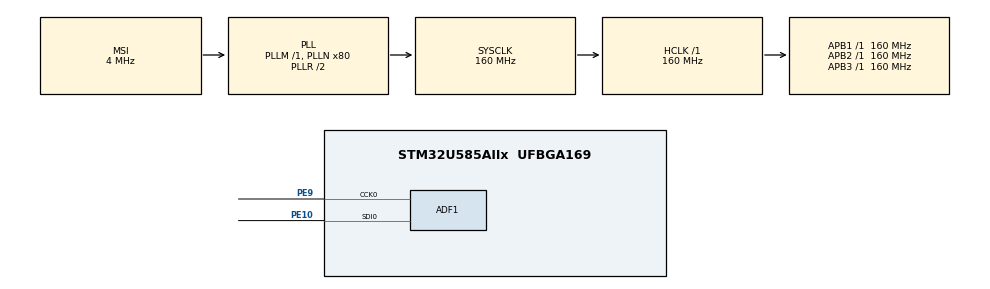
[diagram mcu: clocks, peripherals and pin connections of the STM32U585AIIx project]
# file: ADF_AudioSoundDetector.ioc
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ADF1.MDF_COMPARAM_ActivationOutputClock=ENABLE
ADF1.MDF_COMPARAM_Divider=4
ADF1.MDF_DFLT0_Decimation=64
ADF1.MDF_DFLT0_SADActivation=ENABLE
ADF1.MDF_DFLT0_SADDataMemoryTransfer=MDF_SAD_MEMORY_TRANSFER_ALWAYS
ADF1.MDF_DFLT0_SADMinNoiseLevel=200
ADF1.MDF_DFLT0_SADSignalNoiseThreshold=MDF_SAD_SIGNAL_NOISE_18DB
ADF1.MDF_SITF0_Mode_Display=MDF_SITF_NORMAL_SPI_MODE
ADF1.MDF_SITF0_Threshold=31
CORTEX_M33_NS.userName=CORTEX_M33
LPDMA1.LINKALLOCATEDPORT_LPDMACH0=DMA_LINK_ALLOCATED_PORT1
LPDMA1.LINKEDLISTMODE_LPDMACH0=DMA_LINKEDLIST_CIRCULAR
LPDMA1.PRIORITY_LL_LPDMACH0=DMA_LOW_PRIORITY_HIGH_WEIGHT
Linkedlist.MDMA_Channel0.GP_SW.0.BlkHWRequest=DMA_BREQ_SINGLE_BURST
Linkedlist.MDMA_Channel0.GP_SW.0.DataHandling=NONE
Linkedlist.MDMA_Channel0.GP_SW.0.DataSize=0
Linkedlist.MDMA_Channel0.GP_SW.0.DestDataWidth=DMA_DEST_DATAWIDTH_WORD
Linkedlist.MDMA_Channel0.GP_SW.0.DestInc=DMA_DINC_INCREMENTED
Linkedlist.MDMA_Channel0.GP_SW.0.Direction=DMA_PERIPH_TO_MEMORY
Linkedlist.MDMA_Channel0.GP_SW.0.DstAddress=0
Linkedlist.MDMA_Channel0.GP_SW.0.Instance=MDMA_Channel0
Linkedlist.MDMA_Channel0.GP_SW.0.LL_MASTERDMA=LPDMA
Linkedlist.MDMA_Channel0.GP_SW.0.LL_NAME=MDFQueue
Linkedlist.MDMA_Channel0.GP_SW.0.LL_TYPE=LINEAR
Linkedlist.MDMA_Channel0.GP_SW.0.NODE_NAME=MDFNode
Linkedlist.MDMA_Channel0.GP_SW.0.Requestforcodegen=LPDMA1_REQUEST_ADF1_FLT0
Linkedlist.MDMA_Channel0.GP_SW.0.SrcAddress=0
Linkedlist.MDMA_Channel0.GP_SW.0.SrcDataWidth=DMA_SRC_DATAWIDTH_WORD
Linkedlist.MDMA_Channel0.GP_SW.0.SrcInc=DMA_SINC_FIXED
Linkedlist.MDMA_Channel0.GP_SW.0.TransferEventMode=DMA_TCEM_BLOCK_TRANSFER
Linkedlist.MDMA_Channel0.GP_SW.0.TriggerPolarity=DMA_TRIG_POLARITY_MASKED
Linkedlist.MDMA_Channel0.Request0=GP_SW
Linkedlist.MDMA_Channel0.RequestsNb=1
Linkedlist.RequestSet0=MDMA_Channel0
Linkedlist.RequestSetsNb=1
Mcu.Family=STM32U5
Mcu.Name=STM32U585AIIx
Mcu.Package=UFBGA169
NVIC.ADF1_IRQn=true\:0\:0\:false\:false\:true\:true\:true\:true
NVIC.LPDMA1_Channel0_IRQn=true\:0\:0\:false\:false\:true\:true\:true\:true
NVIC.PriorityGroup=NVIC_PRIORITYGROUP_4
PE10.Mode=MOD_ADF_CCK
PE10.Signal=ADF1_SDI0
PE9.Mode=MOD_MDF_CCK0
PE9.Signal=ADF1_CCK0
PWR.PowerMode=PWR_SMPS_SUPPLY
ProjectManager.HeapSize=0x200
ProjectManager.StackSize=0x400
ProjectManager.TargetToolchain=EWARM V8.50
RCC.ADCFreq_Value=16000000
RCC.AHBFreq_Value=160000000
RCC.APB1Freq_Value=160000000
RCC.APB1TimFreq_Value=160000000
RCC.APB2Freq_Value=160000000
RCC.APB2TimFreq_Value=160000000
RCC.APB3Freq_Value=160000000
RCC.AdfClockSelection=RCC_ADF1CLKSOURCE_MSIK
RCC.CortexFreq_Value=160000000
RCC.DACCLockSelectionVirtual=RCC_DAC1CLKSOURCE_LSI
RCC.DACCLockSelectionVirtualString=RCC_DAC1CLKSOURCE_LSI
RCC.EPOD_VALUE=4000000
RCC.HCLKFreq_Value=160000000
RCC.HSE_VALUE=16000000
RCC.HSI48_VALUE=48000000
RCC.HSI_VALUE=16000000
RCC.LSE_VALUE=32768
RCC.LSIDIV_VALUE=32000
RCC.MSIKClockRange=RCC_MSIKRANGE_3
RCC.MSI_VALUE=4000000
RCC.PLLN=80
RCC.SYSCLKFreq_VALUE=160000000
RCC.SYSCLKSource=RCC_SYSCLKSOURCE_PLLCLK
RCC.USBFreq_Value=48000000
RCC.VCOOutputFreq_Value=320000000
VP_ICACHE_VS_ICACHE.Mode=DirectMappedCache
VP_LPBAMQUEUE_VS_QUEUE.Mode=QUEUEMODE
VP_LPBAM_VS_SIG1.Mode=SmartRun
VP_LPBAM_VS_SIG4.Mode=LPDMA1
VP_LPDMA1_VS_LPDMACH0.Mode=LINKEDLIST_LPDMACH0
VP_PWR_VS_DBSignals.Mode=DisableDeadBatterySignals
VP_PWR_VS_LPOM.Mode=PowerOptimisation
VP_PWR_VS_SECSignals.Mode=Security/Privilege
board=B-U585I-IOT02A

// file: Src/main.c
/* USER CODE BEGIN Header */
/**
  ******************************************************************************
  * @file           : main.c
  * @brief          : Main program body
  ******************************************************************************
  * @attention
  *
  * Copyright (c) 2021 STMicroelectronics.
  * All rights reserved.
  *
  * This software is licensed under terms that can be found in the LICENSE file
  * in the root directory of this software component.
  * If no LICENSE file comes with this software, it is provided AS-IS.
  *
  ******************************************************************************
  */
/* USER CODE END Header */
#include "main.h"

/* USER CODE BEGIN Includes */
#include "linked_list.h"
/* USER CODE END Includes */

MDF_HandleTypeDef AdfHandle0;
MDF_FilterConfigTypeDef AdfFilterConfig0;

DMA_HandleTypeDef handle_LPDMA1_Channel0;

/* USER CODE BEGIN PV */
MDF_DmaConfigTypeDef    DMAConfig;

/*Buffer location and size should aligned to cache line size (32 bytes) */
int16_t RecBuff[REC_BUFF_SIZE * 2U];
/* USER CODE END PV */

void SystemClock_Config(void);
static void SystemPower_Config(void);
static void MX_ICACHE_Init(void);
static void MX_GPIO_Init(void);
static void MX_ADF1_Init(void);
static void MX_LPDMA1_Init(void);
/* USER CODE BEGIN PFP */
static void MDF_DMAConfig(void);
static void EnterLowPowerMode(void);
/* USER CODE END PFP */

/* USER CODE BEGIN 0 */
extern DMA_QListTypeDef MDFQueue;
/* USER CODE END 0 */

int main(void)
{
  /* USER CODE BEGIN 1 */
  /* STM32U5xx HAL library initialization:
       - Configure the Flash prefetch
       - Configure the Systick to generate an interrupt each 1 msec
       - Set NVIC Group Priority to 3
       - Low Level Initialization
     */
  /* USER CODE END 1 */

  /* MCU Configuration--------------------------------------------------------*/

  /* Reset of all peripherals, Initializes the Flash interface and the Systick. */
  HAL_Init();

  /* Configure the system clock */
  SystemClock_Config();

  /* Configure the System Power */
  SystemPower_Config();

  /* Initialize all configured peripherals */
  MX_ICACHE_Init();
  MX_GPIO_Init();
  MX_ADF1_Init();
  MX_LPDMA1_Init();
  /* USER CODE BEGIN 2 */
  BSP_LED_Init(LED_GREEN);
  BSP_LED_Init(LED_RED);
  MX_MDFQueue_Config();

  /* Set queue circular mode for sai queue */
  HAL_DMAEx_List_SetCircularMode(&MDFQueue);

    /* Link SAI queue to DMA channel */
  HAL_DMAEx_List_LinkQ(&handle_LPDMA1_Channel0, &MDFQueue);

  /* Associate the DMA handle */
  __HAL_LINKDMA(&AdfHandle0, hdma, handle_LPDMA1_Channel0);

  /* Configure MDF DMA */
  MDF_DMAConfig();

  /* Start MDF Acquisition */
  if (HAL_MDF_AcqStart_DMA(&AdfHandle0, &AdfFilterConfig0, &DMAConfig) != HAL_OK)
  {
    Error_Handler();
  }
  /* USER CODE END 2 */

  /* Infinite loop */
  /* USER CODE BEGIN WHILE */
  while (1)
  {
    /* Enter the system to Stop 2 mode */
    EnterLowPowerMode();
    /* USER CODE END WHILE */

  }
}

void SystemClock_Config(void)
{
  RCC_OscInitTypeDef RCC_OscInitStruct = {0};
  RCC_ClkInitTypeDef RCC_ClkInitStruct = {0};

  /** Configure the main internal regulator output voltage
  */
  if (HAL_PWREx_ControlVoltageScaling(PWR_REGULATOR_VOLTAGE_SCALE1) != HAL_OK)
  {
    Error_Handler();
  }

  /** Initializes the CPU, AHB and APB busses clocks
  */
  RCC_OscInitStruct.OscillatorType = RCC_OSCILLATORTYPE_MSI|RCC_OSCILLATORTYPE_MSIK;
  RCC_OscInitStruct.MSIState = RCC_MSI_ON;
  RCC_OscInitStruct.MSICalibrationValue = RCC_MSICALIBRATION_DEFAULT;
  RCC_OscInitStruct.MSIClockRange = RCC_MSIRANGE_4;
  RCC_OscInitStruct.MSIKClockRange = RCC_MSIKRANGE_3;
  RCC_OscInitStruct.MSIKState = RCC_MSIK_ON;
  RCC_OscInitStruct.PLL.PLLState = RCC_PLL_ON;
  RCC_OscInitStruct.PLL.PLLSource = RCC_PLLSOURCE_MSI;
  RCC_OscInitStruct.PLL.PLLMBOOST = RCC_PLLMBOOST_DIV1;
  RCC_OscInitStruct.PLL.PLLM = 1;
  RCC_OscInitStruct.PLL.PLLN = 80;
  RCC_OscInitStruct.PLL.PLLP = 2;
  RCC_OscInitStruct.PLL.PLLQ = 2;
  RCC_OscInitStruct.PLL.PLLR = 2;
  RCC_OscInitStruct.PLL.PLLRGE = RCC_PLLVCIRANGE_0;
  RCC_OscInitStruct.PLL.PLLFRACN = 0;
  if (HAL_RCC_OscConfig(&RCC_OscInitStruct) != HAL_OK)
  {
    Error_Handler();
  }

  /** Initializes the CPU, AHB and APB busses clocks
  */
  RCC_ClkInitStruct.ClockType = RCC_CLOCKTYPE_HCLK|RCC_CLOCKTYPE_SYSCLK
                              |RCC_CLOCKTYPE_PCLK1|RCC_CLOCKTYPE_PCLK2
                              |RCC_CLOCKTYPE_PCLK3;
  RCC_ClkInitStruct.SYSCLKSource = RCC_SYSCLKSOURCE_PLLCLK;
  RCC_ClkInitStruct.AHBCLKDivider = RCC_SYSCLK_DIV1;
  RCC_ClkInitStruct.APB1CLKDivider = RCC_HCLK_DIV1;
  RCC_ClkInitStruct.APB2CLKDivider = RCC_HCLK_DIV1;
  RCC_ClkInitStruct.APB3CLKDivider = RCC_HCLK_DIV1;

  if (HAL_RCC_ClockConfig(&RCC_ClkInitStruct, FLASH_LATENCY_4) != HAL_OK)
  {
    Error_Handler();
  }
}

/**
  * @brief Power Configuration
  * @retval None
  */
static void SystemPower_Config(void)
{

  /*
   * Disable the internal Pull-Up in Dead Battery pins of UCPD peripheral
   */
  HAL_PWREx_DisableUCPDDeadBattery();

  /*
   * Switch to SMPS regulator instead of LDO
   */
  if (HAL_PWREx_ConfigSupply(PWR_SMPS_SUPPLY) != HAL_OK)
  {
    Error_Handler();
  }
}

static void MX_ADF1_Init(void)
{

  /**
    AdfHandle0 structure initialization and HAL_MDF_Init function call
  */
  AdfHandle0.Instance = ADF1_Filter0;
  AdfHandle0.Init.CommonParam.ProcClockDivider = 1;
  AdfHandle0.Init.CommonParam.OutputClock.Activation = ENABLE;
  AdfHandle0.Init.CommonParam.OutputClock.Pins = MDF_OUTPUT_CLOCK_0;
  AdfHandle0.Init.CommonParam.OutputClock.Divider = 4;
  AdfHandle0.Init.CommonParam.OutputClock.Trigger.Activation = DISABLE;
  AdfHandle0.Init.SerialInterface.Activation = ENABLE;
  AdfHandle0.Init.SerialInterface.Mode = MDF_SITF_NORMAL_SPI_MODE;
  AdfHandle0.Init.SerialInterface.ClockSource = MDF_SITF_CCK0_SOURCE;
  AdfHandle0.Init.SerialInterface.Threshold = 31;
  AdfHandle0.Init.FilterBistream = MDF_BITSTREAM0_FALLING;
  if (HAL_MDF_Init(&AdfHandle0) != HAL_OK)
  {
    Error_Handler();
  }

  /**
    AdfFilterConfig0 structure initialization

    WARNING : only structure is filled, no specific init function call for filter
  */
  AdfFilterConfig0.DataSource = MDF_DATA_SOURCE_BSMX;
  AdfFilterConfig0.Delay = 0;
  AdfFilterConfig0.CicMode = MDF_ONE_FILTER_SINC4;
  AdfFilterConfig0.DecimationRatio = 64;
  AdfFilterConfig0.Gain = 0;
  AdfFilterConfig0.ReshapeFilter.Activation = DISABLE;
  AdfFilterConfig0.HighPassFilter.Activation = DISABLE;
  AdfFilterConfig0.SoundActivity.Activation = ENABLE;
  AdfFilterConfig0.SoundActivity.Mode = MDF_SAD_VOICE_ACTIVITY_DETECTOR;
  AdfFilterConfig0.SoundActivity.FrameSize = MDF_SAD_8_PCM_SAMPLES;
  AdfFilterConfig0.SoundActivity.Hysteresis = DISABLE;
  AdfFilterConfig0.SoundActivity.SoundTriggerEvent = MDF_SAD_ENTER_DETECT;
  AdfFilterConfig0.SoundActivity.DataMemoryTransfer = MDF_SAD_MEMORY_TRANSFER_ALWAYS;
  AdfFilterConfig0.SoundActivity.MinNoiseLevel = 200;
  AdfFilterConfig0.SoundActivity.HangoverWindow = MDF_SAD_HANGOVER_4_FRAMES;
  AdfFilterConfig0.SoundActivity.LearningFrames = MDF_SAD_LEARNING_2_FRAMES;
  AdfFilterConfig0.SoundActivity.AmbientNoiseSlope = 0;
  AdfFilterConfig0.SoundActivity.SignalNoiseThreshold = MDF_SAD_SIGNAL_NOISE_18DB;
  AdfFilterConfig0.SoundActivity.SoundLevelInterrupt = DISABLE;
  AdfFilterConfig0.AcquisitionMode = MDF_MODE_ASYNC_CONT;
  AdfFilterConfig0.FifoThreshold = MDF_FIFO_THRESHOLD_NOT_EMPTY;
  AdfFilterConfig0.DiscardSamples = 0;

}

static void MX_ICACHE_Init(void)
{

  /** Enable instruction cache in 1-way (direct mapped cache)
  */
  if (HAL_ICACHE_ConfigAssociativityMode(ICACHE_1WAY) != HAL_OK)
  {
    Error_Handler();
  }
  if (HAL_ICACHE_Enable() != HAL_OK)
  {
    Error_Handler();
  }

}

static void MX_LPDMA1_Init(void)
{

  /* Peripheral clock enable */
  __HAL_RCC_LPDMA1_CLK_ENABLE();

  /* LPDMA1 interrupt Init */
    HAL_NVIC_SetPriority(LPDMA1_Channel0_IRQn, 0, 0);
    HAL_NVIC_EnableIRQ(LPDMA1_Channel0_IRQn);

  handle_LPDMA1_Channel0.Instance = LPDMA1_Channel0;
  handle_LPDMA1_Channel0.InitLinkedList.Priority = DMA_LOW_PRIORITY_HIGH_WEIGHT;
  handle_LPDMA1_Channel0.InitLinkedList.LinkStepMode = DMA_LSM_FULL_EXECUTION;
  handle_LPDMA1_Channel0.InitLinkedList.LinkAllocatedPort = DMA_LINK_ALLOCATED_PORT1;
  handle_LPDMA1_Channel0.InitLinkedList.TransferEventMode = DMA_TCEM_LAST_LL_ITEM_TRANSFER;
  handle_LPDMA1_Channel0.InitLinkedList.LinkedListMode = DMA_LINKEDLIST_CIRCULAR;
  if (HAL_DMAEx_List_Init(&handle_LPDMA1_Channel0) != HAL_OK)
  {
    Error_Handler();
  }
  if (HAL_DMA_ConfigChannelAttributes(&handle_LPDMA1_Channel0, DMA_CHANNEL_NPRIV) != HAL_OK)
  {
    Error_Handler();
  }

}

static void MX_GPIO_Init(void)
{

  /* GPIO Ports Clock Enable */
  __HAL_RCC_GPIOE_CLK_ENABLE();

}

/* USER CODE BEGIN 4 */
/**
  * @brief  MDF DMA configuration
  * @param  None
  * @retval None
  */
static void MDF_DMAConfig(void)
{
  /* Initialize DMA configuration parameters */
  DMAConfig.Address                              = (uint32_t)&RecBuff[0];
  DMAConfig.DataLength                           = (REC_BUFF_SIZE * 4U);
  DMAConfig.MsbOnly                              = DISABLE;
}

/**
  * @brief  Enter low power mode
  * @param  None
  * @retval None
  */
static void EnterLowPowerMode(void)
{
    /* Enable Power Control clock */
  __HAL_RCC_PWR_CLK_ENABLE();

  /* Enter the system to STOP2 mode */
  HAL_PWREx_EnterSTOP2Mode(PWR_STOPENTRY_WFI);
}

/**
  * @brief  MDF sound activity detector callback.
  * @param  hmdf MDF handle.
  * @retval None.
  */
void HAL_MDF_SadCallback(MDF_HandleTypeDef *hmdf)
{
  BSP_LED_Toggle(LED_GREEN);
}

/* USER CODE END 4 */

void Error_Handler(void)
{
  __disable_irq();
  while (1)
  {
  }
}
